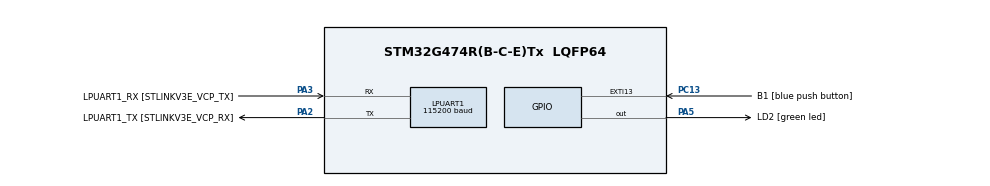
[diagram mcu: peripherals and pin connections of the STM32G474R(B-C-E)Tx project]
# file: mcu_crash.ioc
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LPUART1.BaudRate=115200
LPUART1.WordLength=UART_WORDLENGTH_8B
Mcu.Family=STM32G4
Mcu.Name=STM32G474R(B-C-E)Tx
Mcu.Package=LQFP64
NVIC.EXTI15_10_IRQn=true\:0\:0\:false\:false\:true\:true\:true\:true
NVIC.PriorityGroup=NVIC_PRIORITYGROUP_4
PA13.GPIO_Label=T_SWDIO
PA13.Mode=Serial_Wire
PA13.Signal=SYS_JTMS-SWDIO
PA14.GPIO_Label=T_SWCLK
PA14.Mode=Serial_Wire
PA14.Signal=SYS_JTCK-SWCLK
PA2.GPIO_Label=LPUART1_TX [STLINKV3E_VCP_RX]
PA2.Mode=Asynchronous
PA2.Signal=LPUART1_TX
PA3.GPIO_Label=LPUART1_RX [STLINKV3E_VCP_TX]
PA3.Mode=Asynchronous
PA3.Signal=LPUART1_RX
PA5.GPIO_Label=LD2 [green led]
PA5.Signal=GPIO_Output
PB3.GPIO_Label=T_SWO
PB3.Signal=SYS_JTDO-SWO
PC13.GPIO_Label=B1 [blue push button]
PC13.Signal=GPXTI13
PC14-OSC32_IN.Mode=LSE-External-Oscillator
PC14-OSC32_IN.Signal=RCC_OSC32_IN
PC15-OSC32_OUT.Mode=LSE-External-Oscillator
PC15-OSC32_OUT.Signal=RCC_OSC32_OUT
PF0-OSC_IN.Mode=HSE-External-Oscillator
PF0-OSC_IN.Signal=RCC_OSC_IN
PF1-OSC_OUT.Mode=HSE-External-Oscillator
PF1-OSC_OUT.Signal=RCC_OSC_OUT
ProjectManager.HeapSize=0x200
ProjectManager.StackSize=0x400
ProjectManager.TargetToolchain=STM32CubeIDE
RCC.ADC12Freq_Value=170000000
RCC.ADC345Freq_Value=170000000
RCC.AHBFreq_Value=170000000
RCC.APB1Freq_Value=170000000
RCC.APB1TimFreq_Value=170000000
RCC.APB2Freq_Value=170000000
RCC.APB2TimFreq_Value=170000000
RCC.CortexFreq_Value=170000000
RCC.EXTERNAL_CLOCK_VALUE=12288000
RCC.HCLKFreq_Value=170000000
RCC.HSE_VALUE=24000000
RCC.HSI48_VALUE=48000000
RCC.HSI_VALUE=16000000
RCC.PLLM=RCC_PLLM_DIV4
RCC.PLLN=85
RCC.RTCClockSelection=RCC_RTCCLKSOURCE_LSE
RCC.SYSCLKFreq_VALUE=170000000
RCC.SYSCLKSource=RCC_SYSCLKSOURCE_PLLCLK
RCC.USBFreq_Value=170000000
RCC.VCOOutputFreq_Value=340000000
VP_SYS_VS_DBSignals.Mode=DisableDeadBatterySignals
board=NUCLEO-G474RE

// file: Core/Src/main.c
/* USER CODE BEGIN Header */
/**
  ******************************************************************************
  * @file           : main.c
  * @brief          : Main program body
  ******************************************************************************
  * @attention
  *
  * Copyright (c) 2024 STMicroelectronics.
  * All rights reserved.
  *
  * This software is licensed under terms that can be found in the LICENSE file
  * in the root directory of this software component.
  * If no LICENSE file comes with this software, it is provided AS-IS.
  *
  ******************************************************************************
  */
/* USER CODE END Header */
#include "main.h"
#include "usart.h"
#include "gpio.h"

/* USER CODE BEGIN Includes */
#include "my_threads.h"
#include "hw_abstraction.h"
#include "project_config.h"
/* USER CODE END Includes */

void SystemClock_Config(void);

int main(void)
{

  /* MCU Configuration--------------------------------------------------------*/

  /* Reset of all peripherals, Initializes the Flash interface and the Systick. */
  LL_APB2_GRP1_EnableClock(LL_APB2_GRP1_PERIPH_SYSCFG);
  LL_APB1_GRP1_EnableClock(LL_APB1_GRP1_PERIPH_PWR);

  /* System interrupt init*/
  NVIC_SetPriorityGrouping(NVIC_PRIORITYGROUP_4);

  /** Disable the internal Pull-Up in Dead Battery pins of UCPD peripheral
  */
  LL_PWR_DisableUCPDDeadBattery();

  /* Configure the system clock */
  SystemClock_Config();

  /* Initialize all configured peripherals */
  MX_GPIO_Init();
  MX_LPUART1_UART_Init();
  /* USER CODE BEGIN 2 */
  HwAbstraction_LedSetup();

  PseudoOS_Thread_Create(&idle_th, idle_task, idle_stack, sizeof(idle_stack), 0);
  PseudoOS_Thread_Create(&red_th, pseudo_task_red_led, red_stack, sizeof(red_stack), 2);
  PseudoOS_Thread_Create(&blue_th, pseudo_task_blue_led, blue_stack, sizeof(blue_stack), 3);
  SysTick->CTRL |= SysTick_CTRL_TICKINT_Msk;
  PseudoOS_Start();
  /* USER CODE END 2 */

  /* Infinite loop */
  while (1)
  {

	  /* simple led blinking */
	  //LD2_GPIO_Port->ODR ^= LD2_Pin;
	  LL_mDelay(200);
  }
}

void SystemClock_Config(void)
{
  LL_FLASH_SetLatency(LL_FLASH_LATENCY_4);
  while(LL_FLASH_GetLatency() != LL_FLASH_LATENCY_4)
  {
  }
  LL_PWR_EnableRange1BoostMode();
  LL_RCC_HSI_Enable();
   /* Wait till HSI is ready */
  while(LL_RCC_HSI_IsReady() != 1)
  {
  }

  LL_RCC_HSI_SetCalibTrimming(64);
  LL_RCC_PLL_ConfigDomain_SYS(LL_RCC_PLLSOURCE_HSI, LL_RCC_PLLM_DIV_4, 85, LL_RCC_PLLR_DIV_2);
  LL_RCC_PLL_EnableDomain_SYS();
  LL_RCC_PLL_Enable();
   /* Wait till PLL is ready */
  while(LL_RCC_PLL_IsReady() != 1)
  {
  }

  LL_RCC_SetSysClkSource(LL_RCC_SYS_CLKSOURCE_PLL);
  LL_RCC_SetAHBPrescaler(LL_RCC_SYSCLK_DIV_2);
   /* Wait till System clock is ready */
  while(LL_RCC_GetSysClkSource() != LL_RCC_SYS_CLKSOURCE_STATUS_PLL)
  {
  }

  /* Insure 1us transition state at intermediate medium speed clock*/
  for (__IO uint32_t i = (170 >> 1); i !=0; i--);

  /* Set AHB prescaler*/
  LL_RCC_SetAHBPrescaler(LL_RCC_SYSCLK_DIV_1);
  LL_RCC_SetAPB1Prescaler(LL_RCC_APB1_DIV_1);
  LL_RCC_SetAPB2Prescaler(LL_RCC_APB2_DIV_1);

  LL_Init1msTick(170000000);

  LL_SetSystemCoreClock(170000000);
}

void Error_Handler(void)
{
  __disable_irq();
  while (1)
  {
  }
}
